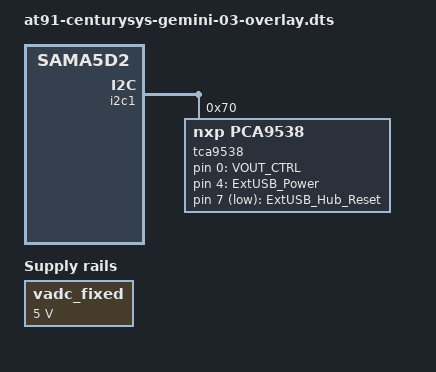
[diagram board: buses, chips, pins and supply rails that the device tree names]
// SPDX-License-Identifier: (GPL-2.0+ OR MIT)
/*
 * at91-centurysys-gemini-03-overlay.dts - Device Tree Overlay file (xio_id: 0x03)
 *                                           for Century Systems Gemini board
 *
 *  Copyright (C) 2020 Century Systems
 *                     Takeyoshi Kikuchi <kikuchi@centurysys.co.jp>
 */

/dts-v1/;
/plugin/;
#include "sama5d2-pinfunc.h"
#include <dt-bindings/mfd/atmel-flexcom.h>
#include <dt-bindings/gpio/gpio.h>
#include <dt-bindings/regulator/active-semi,8945a-regulator.h>

/ {
	compatible = "atmel,sama5d2-gemini", "atmel,sama5d2", "atmel,sama5";

	fragment@0 {
		target-path = "/";
		__overlay__ {
			vadc_fixed: fixedregulator_adc {
				compatible = "regulator-fixed";
				regulator-name = "VADC_5V";
				regulator-min-microvolt = <5000000>;
				regulator-max-microvolt = <5000000>;
			};
		};
	};

	fragment@1 {
		target = <&i2c1>;
		__overlay__ {
			#address-cells = <1>;
			#size-cells = <0>;

			tca9538: tca9538@70 {
				compatible = "nxp,pca9538";
				reg = <0x70>;
				#address-cells = <1>;
				#size-cells = <0>;
				#gpio-cells = <2>;

				gpio-line-names = "eFUSE_SHDN_N",
						  "eFUSE_FLT_N",
						  "Reserved2",
						  "Reserved3",
						  "ExtUSB_Power_Enable",
						  "Reserved5",
						  "Reserved6",
						  "ExtUSB_Hub_Reset";
			};
		};
	};

	fragment@2 {
		target = <&leds>;
		__overlay__ {
			tca953x_efuse_shdn_n {
				label = "VOUT_CTRL";
				gpios = <&tca9538 0 GPIO_ACTIVE_HIGH>;
			};

			tca953x_usb_power_enable {
				label = "ExtUSB_Power";
				gpios = <&tca9538 4 GPIO_ACTIVE_HIGH>;
				default-state = "on";
			};

			tca953x_usb_hub_reset {
				label = "ExtUSB_Hub_Reset";
				gpios = <&tca9538 7 GPIO_ACTIVE_LOW>;
				default-state = "off";
				linux,default-trigger = "oneshot";
				led-pattern = <500 100>;
			};
		};
	};
};
